# STM32F100xx register map
File version: 1.1
Registers are 32-bit, read-write, reset 0x0 unless marked. A register's access mark holds for its fields unless they carry their own. Offsets are from the block's base; [hi:lo] are bit positions; lines under a group give offsets from that group; {n}, {i} and the like mark numbered series.

## SPI1 — Serial peripheral interface
Base 0x40013000
Same registers: SPI2 0x40003800, SPI3 0x40003C00
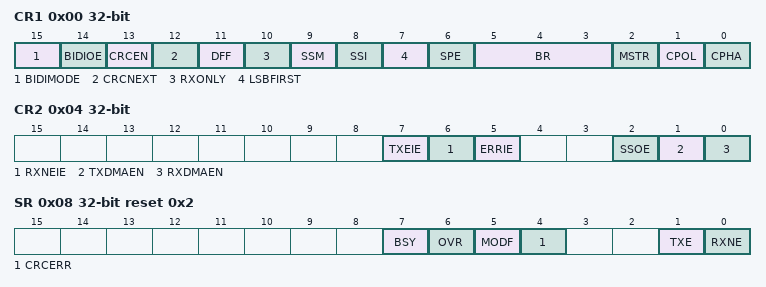
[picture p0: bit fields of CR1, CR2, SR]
0x00 CR1 — control register 1
  [15] BIDIMODE — Bidirectional data mode enable
  [14] BIDIOE — Output enable in bidirectional mode
  [13] CRCEN — Hardware CRC calculation enable
  [12] CRCNEXT — CRC transfer next
  [11] DFF — Data frame format
  [10] RXONLY — Receive only
  [9] SSM — Software slave management
  [8] SSI — Internal slave select
  [7] LSBFIRST — Frame format
  [6] SPE — SPI enable
  [5:3] BR — Baud rate control
  [2] MSTR — Master selection
  [1] CPOL — Clock polarity
  [0] CPHA — Clock phase
0x04 CR2 — control register 2
  [7] TXEIE — Tx buffer empty interrupt enable
  [6] RXNEIE — RX buffer not empty interrupt enable
  [5] ERRIE — Error interrupt enable
  [2] SSOE — SS output enable
  [1] TXDMAEN — Tx buffer DMA enable
  [0] RXDMAEN — Rx buffer DMA enable
0x08 SR access per field reset 0x2 — status register
  [7] BSY ro — Busy flag
  [6] OVR ro — Overrun flag
  [5] MODF ro — Mode fault
  [4] CRCERR rw — CRC error flag
  [1] TXE ro — Transmit buffer empty
  [0] RXNE ro — Receive buffer not empty
0x0C DR — data register
  [15:0] DR — Data register
0x10 CRCPR reset 0x7 — CRC polynomial register
  [15:0] CRCPOLY
0x14 RXCRCR ro — RX CRC register
  [15:0] RxCRC
0x18 TXCRCR ro — TX CRC register
  [15:0] TxCRC

## USART1 — Universal synchronous asynchronous receiver transmitter
Base 0x40013800
Same registers: USART2 0x40004400, USART3 0x40004800
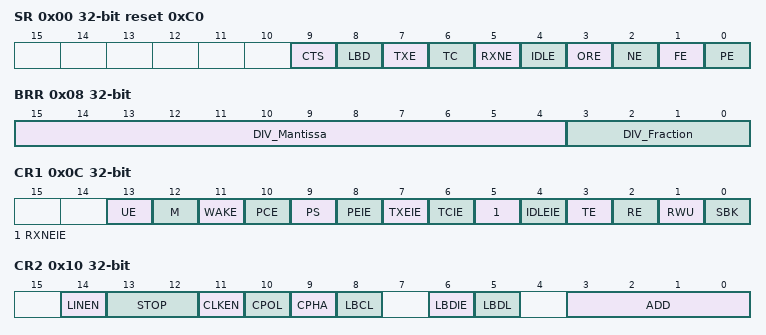
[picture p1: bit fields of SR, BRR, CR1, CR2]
0x00 SR access per field reset 0xC0 — Status register
  [9] CTS rw — CTS flag
  [8] LBD rw — LIN break detection flag
  [7] TXE ro — Transmit data register empty
  [6] TC rw — Transmission complete
  [5] RXNE rw — Read data register not empty
  [4] IDLE ro — IDLE line detected
  [3] ORE ro — Overrun error
  [2] NE ro — Noise error flag
  [1] FE ro — Framing error
  [0] PE ro — Parity error
0x04 DR — Data register
  [8:0] DR — Data value
0x08 BRR — Baud rate register
  [15:4] DIV_Mantissa — mantissa of USARTDIV
  [3:0] DIV_Fraction — fraction of USARTDIV
0x0C CR1 — Control register 1
  [13] UE — USART enable
  [12] M — Word length
  [11] WAKE — Wakeup method
  [10] PCE — Parity control enable
  [9] PS — Parity selection
  [8] PEIE — PE interrupt enable
  [7] TXEIE — TXE interrupt enable
  [6] TCIE — Transmission complete interrupt enable
  [5] RXNEIE — RXNE interrupt enable
  [4] IDLEIE — IDLE interrupt enable
  [3] TE — Transmitter enable
  [2] RE — Receiver enable
  [1] RWU — Receiver wakeup
  [0] SBK — Send break
0x10 CR2 — Control register 2
  [14] LINEN — LIN mode enable
  [13:12] STOP — STOP bits
  [11] CLKEN — Clock enable
  [10] CPOL — Clock polarity
  [9] CPHA — Clock phase
  [8] LBCL — Last bit clock pulse
  [6] LBDIE — LIN break detection interrupt enable
  [5] LBDL — lin break detection length
  [3:0] ADD — Address of the USART node
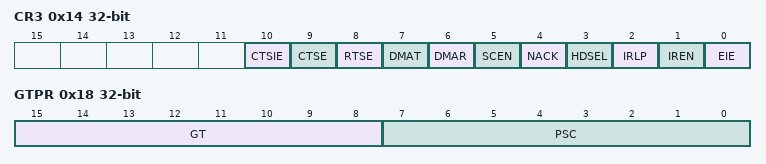
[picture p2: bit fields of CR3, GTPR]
0x14 CR3 — Control register 3
  [10] CTSIE — CTS interrupt enable
  [9] CTSE — CTS enable
  [8] RTSE — RTS enable
  [7] DMAT — DMA enable transmitter
  [6] DMAR — DMA enable receiver
  [5] SCEN — Smartcard mode enable
  [4] NACK — Smartcard NACK enable
  [3] HDSEL — Half-duplex selection
  [2] IRLP — IrDA low-power
  [1] IREN — IrDA mode enable
  [0] EIE — Error interrupt enable
0x18 GTPR — Guard time and prescaler register
  [15:8] GT — Guard time value
  [7:0] PSC range 0..65535 — Prescaler value

## ADC1 — Analog to digital converter
Base 0x40012400
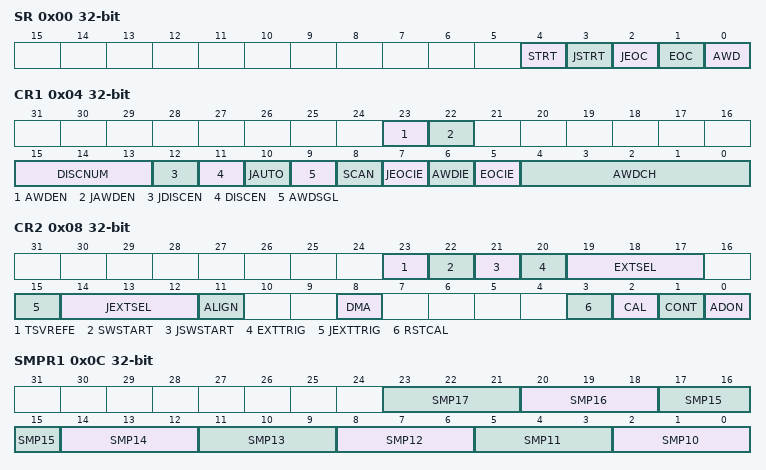
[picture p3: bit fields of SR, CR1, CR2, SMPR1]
0x00 SR — status register
  [4] STRT — Regular channel start flag
  [3] JSTRT — Injected channel start flag
  [2] JEOC — Injected channel end of conversion
  [1] EOC — Regular channel end of conversion
  [0] AWD — Analog watchdog flag
0x04 CR1 — control register 1
  [23] AWDEN — Analog watchdog enable on regular channels
  [22] JAWDEN — Analog watchdog enable on injected channels
  [15:13] DISCNUM — Discontinuous mode channel count
  [12] JDISCEN — Discontinuous mode on injected channels
  [11] DISCEN — Discontinuous mode on regular channels
  [10] JAUTO — Automatic injected group conversion
  [9] AWDSGL — Enable the watchdog on a single channel in scan mode
  [8] SCAN — Scan mode
  [7] JEOCIE — Interrupt enable for injected channels
  [6] AWDIE — Analog watchdog interrupt enable
  [5] EOCIE — Interrupt enable for EOC
  [4:0] AWDCH — Analog watchdog channel select bits
0x08 CR2 — control register 2
  [23] TSVREFE — Temperature sensor and VREFINT enable
  [22] SWSTART — Start conversion of regular channels
  [21] JSWSTART — Start conversion of injected channels
  [20] EXTTRIG — External trigger conversion mode for regular channels
  [19:17] EXTSEL — External event select for regular group
  [15] JEXTTRIG — External trigger conversion mode for injected channels
  [14:12] JEXTSEL — External event select for injected group
  [11] ALIGN — Data alignment
  [8] DMA — Direct memory access mode
  [3] RSTCAL — Reset calibration
  [2] CAL — A/D calibration
  [1] CONT — Continuous conversion
  [0] ADON — A/D converter ON / OFF
0x0C SMPR1 — sample time register 1
  [3n-28:3n-30] SMP{n} (n=10..17) — Channel {n} sample time selection
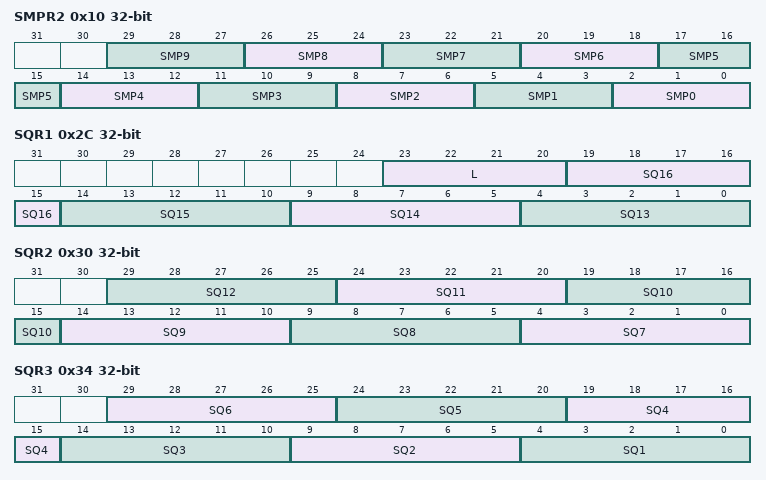
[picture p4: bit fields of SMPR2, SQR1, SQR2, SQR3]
0x10 SMPR2 — sample time register 2
  [3n+2:3n] SMP{n} (n=0..9) — Channel {n} sample time selection
{0x10+4i} JOFR{i} (i=1..4) — injected channel data offset register x
  [11:0] JOFFSET{i} — Data offset for injected channel {i}
0x24 HTR reset 0xFFF — watchdog higher threshold register
  [11:0] HT — Analog watchdog higher threshold
0x28 LTR — watchdog lower threshold register
  [11:0] LT — Analog watchdog lower threshold
0x2C SQR1 — regular sequence register 1
  [23:20] L — Regular channel sequence length
  [5n-61:5n-65] SQ{n} (n=13..16) — {n}th conversion in regular sequence
0x30 SQR2 — regular sequence register 2
  [5n-31:5n-35] SQ{n} (n=7..12) — {n}th conversion in regular sequence
0x34 SQR3 — regular sequence register 3
  [29:25] SQ6 — 6th conversion in regular sequence
  [24:20] SQ5 — 5th conversion in regular sequence
  [19:15] SQ4 — 4th conversion in regular sequence
  [14:10] SQ3 — 3rd conversion in regular sequence
  [9:5] SQ2 — 2nd conversion in regular sequence
  [4:0] SQ1 — 1st conversion in regular sequence
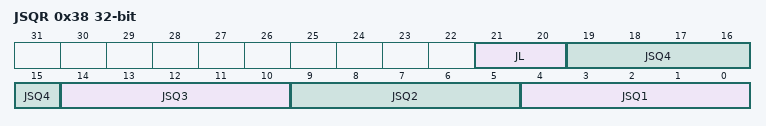
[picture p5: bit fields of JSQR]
0x38 JSQR — injected sequence register
  [21:20] JL — Injected sequence length
  [19:15] JSQ4 — 4th conversion in injected sequence
  [14:10] JSQ3 — 3rd conversion in injected sequence
  [9:5] JSQ2 — 2nd conversion in injected sequence
  [4:0] JSQ1 — 1st conversion in injected sequence
{0x38+4i} JDR{i} ro (i=1..4) — injected data register x
  [15:0] JDATA — Injected data
0x4C DR ro — regular data register
  [15:0] DATA — Regular data
